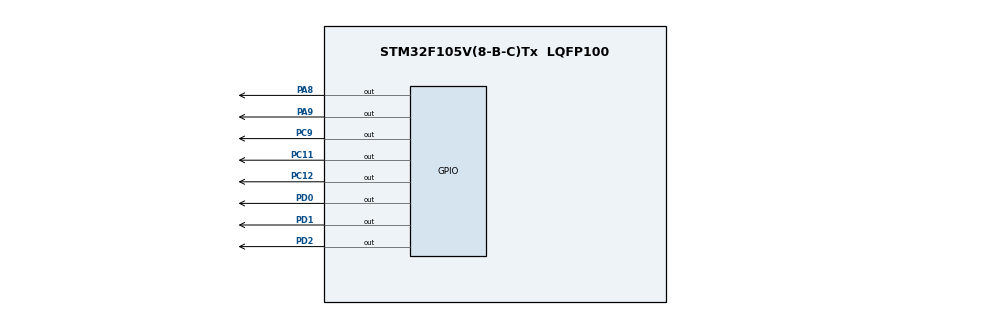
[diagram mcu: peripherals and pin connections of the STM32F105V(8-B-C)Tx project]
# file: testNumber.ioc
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Mcu.Family=STM32F1
Mcu.Name=STM32F105V(8-B-C)Tx
Mcu.Package=LQFP100
NVIC.PriorityGroup=NVIC_PRIORITYGROUP_4
NVIC.TIM6_IRQn=true\:0\:0\:false\:false\:true\:true\:true
PA13.Mode=Serial_Wire
PA13.Signal=SYS_JTMS-SWDIO
PA14.Mode=Serial_Wire
PA14.Signal=SYS_JTCK-SWCLK
PA8.PinState=GPIO_PIN_SET
PA8.Signal=GPIO_Output
PA9.PinState=GPIO_PIN_SET
PA9.Signal=GPIO_Output
PC11.PinState=GPIO_PIN_SET
PC11.Signal=GPIO_Output
PC12.PinState=GPIO_PIN_SET
PC12.Signal=GPIO_Output
PC9.PinState=GPIO_PIN_SET
PC9.Signal=GPIO_Output
PD0.PinState=GPIO_PIN_SET
PD0.Signal=GPIO_Output
PD1.PinState=GPIO_PIN_SET
PD1.Signal=GPIO_Output
PD2.PinState=GPIO_PIN_SET
PD2.Signal=GPIO_Output
ProjectManager.HeapSize=0x200
ProjectManager.StackSize=0x400
ProjectManager.TargetToolchain=Makefile
RCC.USBFreq_Value=10666666.666666666
TIM6.Period=2000
TIM6.Prescaler=3999
VP_TIM6_VS_ClockSourceINT.Mode=Enable_Timer
board=custom

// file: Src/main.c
/* USER CODE BEGIN Header */
/**
  ******************************************************************************
  * @file           : main.c
  * @brief          : Main program body
  ******************************************************************************
  * @attention
  *
  * <h2><center>&copy; Copyright (c) 2019 STMicroelectronics.
  * All rights reserved.</center></h2>
  *
  * This software component is licensed by ST under BSD 3-Clause license,
  * the "License"; You may not use this file except in compliance with the
  * License. You may obtain a copy of the License at:
  *                        opensource.org/licenses/BSD-3-Clause
  *
  ******************************************************************************
  */
/* USER CODE END Header */

#include "main.h"

TIM_HandleTypeDef htim6;

void SystemClock_Config(void);
static void MX_GPIO_Init(void);
static void MX_TIM6_Init(void);

int main(void)
{
  /* USER CODE BEGIN 1 */
  uint16_t i;
  /* USER CODE END 1 */

  /* MCU Configuration--------------------------------------------------------*/

  /* Reset of all peripherals, Initializes the Flash interface and the Systick. */
  HAL_Init();

  /* Configure the system clock */
  SystemClock_Config();

  /* Initialize all configured peripherals */
  MX_GPIO_Init();
  MX_TIM6_Init();
  /* USER CODE BEGIN 2 */
  HAL_TIM_Base_Start_IT(&htim6);
  //ledprint(123);
  /* USER CODE END 2 */

  /* Infinite loop */
  while (1)
  {

    /* USER CODE BEGIN 3 */
    for (i = 123; i < 334; i = i + 50)
    {
      ledprint(i);
      HAL_Delay(1000);
    }
  }
  /* USER CODE END 3 */
}

void SystemClock_Config(void)
{
  RCC_OscInitTypeDef RCC_OscInitStruct = {0};
  RCC_ClkInitTypeDef RCC_ClkInitStruct = {0};

  /** Initializes the CPU, AHB and APB busses clocks
  */
  RCC_OscInitStruct.OscillatorType = RCC_OSCILLATORTYPE_HSI;
  RCC_OscInitStruct.HSIState = RCC_HSI_ON;
  RCC_OscInitStruct.HSICalibrationValue = RCC_HSICALIBRATION_DEFAULT;
  RCC_OscInitStruct.PLL.PLLState = RCC_PLL_NONE;
  RCC_OscInitStruct.PLL2.PLL2State = RCC_PLL_NONE;
  if (HAL_RCC_OscConfig(&RCC_OscInitStruct) != HAL_OK)
  {
    Error_Handler();
  }
  /** Initializes the CPU, AHB and APB busses clocks
  */
  RCC_ClkInitStruct.ClockType = RCC_CLOCKTYPE_HCLK|RCC_CLOCKTYPE_SYSCLK
                              |RCC_CLOCKTYPE_PCLK1|RCC_CLOCKTYPE_PCLK2;
  RCC_ClkInitStruct.SYSCLKSource = RCC_SYSCLKSOURCE_HSI;
  RCC_ClkInitStruct.AHBCLKDivider = RCC_SYSCLK_DIV1;
  RCC_ClkInitStruct.APB1CLKDivider = RCC_HCLK_DIV1;
  RCC_ClkInitStruct.APB2CLKDivider = RCC_HCLK_DIV1;

  if (HAL_RCC_ClockConfig(&RCC_ClkInitStruct, FLASH_LATENCY_0) != HAL_OK)
  {
    Error_Handler();
  }
  /** Configure the Systick interrupt time
  */
  __HAL_RCC_PLLI2S_ENABLE();
}

static void MX_TIM6_Init(void)
{

  TIM_MasterConfigTypeDef sMasterConfig = {0};

  htim6.Instance = TIM6;
  htim6.Init.Prescaler = 3999;
  htim6.Init.CounterMode = TIM_COUNTERMODE_UP;
  htim6.Init.Period = 10;
  htim6.Init.AutoReloadPreload = TIM_AUTORELOAD_PRELOAD_DISABLE;
  if (HAL_TIM_Base_Init(&htim6) != HAL_OK)
  {
    Error_Handler();
  }
  sMasterConfig.MasterOutputTrigger = TIM_TRGO_RESET;
  sMasterConfig.MasterSlaveMode = TIM_MASTERSLAVEMODE_DISABLE;
  if (HAL_TIMEx_MasterConfigSynchronization(&htim6, &sMasterConfig) != HAL_OK)
  {
    Error_Handler();
  }

}

static void MX_GPIO_Init(void)
{
  GPIO_InitTypeDef GPIO_InitStruct = {0};

  /* GPIO Ports Clock Enable */
  __HAL_RCC_GPIOC_CLK_ENABLE();
  __HAL_RCC_GPIOA_CLK_ENABLE();
  __HAL_RCC_GPIOD_CLK_ENABLE();

  /*Configure GPIO pin Output Level */
  HAL_GPIO_WritePin(GPIOC, GPIO_PIN_9|GPIO_PIN_11|GPIO_PIN_12, GPIO_PIN_SET);

  /*Configure GPIO pin Output Level */
  HAL_GPIO_WritePin(GPIOA, GPIO_PIN_8|GPIO_PIN_9, GPIO_PIN_SET);

  /*Configure GPIO pin Output Level */
  HAL_GPIO_WritePin(GPIOD, GPIO_PIN_0|GPIO_PIN_1|GPIO_PIN_2, GPIO_PIN_SET);

  /*Configure GPIO pins : PC9 PC11 PC12 */
  GPIO_InitStruct.Pin = GPIO_PIN_9|GPIO_PIN_11|GPIO_PIN_12;
  GPIO_InitStruct.Mode = GPIO_MODE_OUTPUT_PP;
  GPIO_InitStruct.Pull = GPIO_NOPULL;
  GPIO_InitStruct.Speed = GPIO_SPEED_FREQ_LOW;
  HAL_GPIO_Init(GPIOC, &GPIO_InitStruct);

  /*Configure GPIO pins : PA8 PA9 */
  GPIO_InitStruct.Pin = GPIO_PIN_8|GPIO_PIN_9;
  GPIO_InitStruct.Mode = GPIO_MODE_OUTPUT_PP;
  GPIO_InitStruct.Pull = GPIO_NOPULL;
  GPIO_InitStruct.Speed = GPIO_SPEED_FREQ_LOW;
  HAL_GPIO_Init(GPIOA, &GPIO_InitStruct);

  /*Configure GPIO pins : PD0 PD1 PD2 */
  GPIO_InitStruct.Pin = GPIO_PIN_0|GPIO_PIN_1|GPIO_PIN_2;
  GPIO_InitStruct.Mode = GPIO_MODE_OUTPUT_PP;
  GPIO_InitStruct.Pull = GPIO_NOPULL;
  GPIO_InitStruct.Speed = GPIO_SPEED_FREQ_LOW;
  HAL_GPIO_Init(GPIOD, &GPIO_InitStruct);

}

void Error_Handler(void)
{
}

/************************ (C) COPYRIGHT STMicroelectronics *****END OF FILE****/
